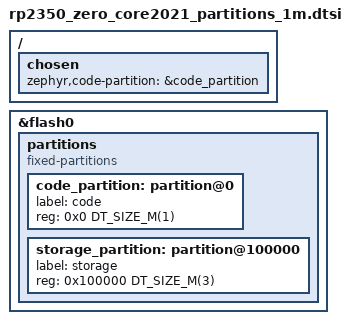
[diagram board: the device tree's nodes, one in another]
/*
 * Copyright (c) 2026 zlrs contributors
 *
 * SPDX-License-Identifier: Apache-2.0
 *
 * Partition table without a bootloader: the 4 MB flash splits into 1 MB code and 3 MB storage
 * (NVS holds keys and pairing records). MCUboot variants use the Zephyr tree's
 * raspberrypi/partitions_4M_sysbuild.dtsi, see the README's partition table.
 */

&flash0 {
	partitions {
		compatible = "fixed-partitions";
		#address-cells = <1>;
		#size-cells = <1>;

		code_partition: partition@0 {
			label = "code";
			reg = <0x0 DT_SIZE_M(1)>;
		};

		storage_partition: partition@100000 {
			label = "storage";
			reg = <0x100000 DT_SIZE_M(3)>;
		};
	};
};

/ {
	chosen {
		zephyr,code-partition = &code_partition;
	};
};
